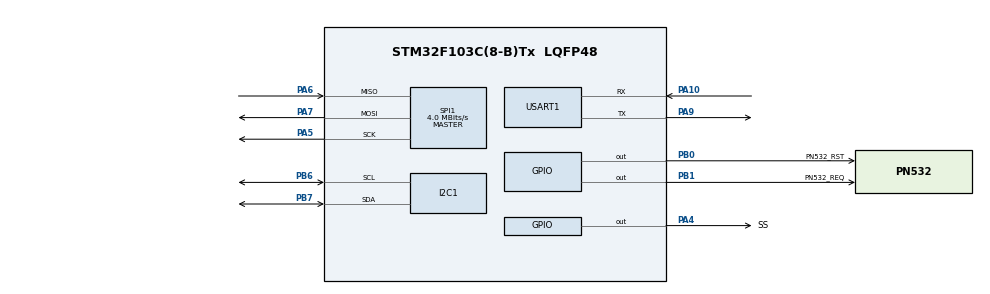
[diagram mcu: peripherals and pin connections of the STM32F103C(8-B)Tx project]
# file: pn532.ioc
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Mcu.Family=STM32F1
Mcu.Name=STM32F103C(8-B)Tx
Mcu.Package=LQFP48
NVIC.PriorityGroup=NVIC_PRIORITYGROUP_4
PA10.Mode=Asynchronous
PA10.Signal=USART1_RX
PA13.Mode=Serial_Wire
PA13.Signal=SYS_JTMS-SWDIO
PA14.Mode=Serial_Wire
PA14.Signal=SYS_JTCK-SWCLK
PA4.GPIO_Label=SS
PA4.GPIO_PuPd=GPIO_PULLUP
PA4.Signal=GPIO_Output
PA5.Mode=Full_Duplex_Master
PA5.Signal=SPI1_SCK
PA6.Mode=Full_Duplex_Master
PA6.Signal=SPI1_MISO
PA7.Mode=Full_Duplex_Master
PA7.Signal=SPI1_MOSI
PA9.Mode=Asynchronous
PA9.Signal=USART1_TX
PB0.GPIO_Label=PN532_RST
PB0.GPIO_PuPd=GPIO_PULLUP
PB0.Signal=GPIO_Output
PB1.GPIO_Label=PN532_REQ
PB1.GPIO_PuPd=GPIO_PULLUP
PB1.Signal=GPIO_Output
PB6.Mode=I2C
PB6.Signal=I2C1_SCL
PB7.Mode=I2C
PB7.Signal=I2C1_SDA
ProjectManager.HeapSize=0x200
ProjectManager.StackSize=0x400
ProjectManager.TargetToolchain=STM32CubeIDE
RCC.APB1Freq_Value=8000000
RCC.APB2Freq_Value=8000000
SPI1.CalculateBaudRate=4.0 MBits/s
SPI1.Direction=SPI_DIRECTION_2LINES
SPI1.Mode=SPI_MODE_MASTER
SPI1.VirtualType=VM_MASTER
USART1.VirtualMode=VM_ASYNC
board=custom

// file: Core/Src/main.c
/* USER CODE BEGIN Header */
/**
  ******************************************************************************
  * @file           : main.c
  * @brief          : Main program body
  ******************************************************************************
  * @attention
  *
  * <h2><center>&copy; Copyright (c) 2023 STMicroelectronics.
  * All rights reserved.</center></h2>
  *
  * This software component is licensed by ST under BSD 3-Clause license,
  * the "License"; You may not use this file except in compliance with the
  * License. You may obtain a copy of the License at:
  *                        opensource.org/licenses/BSD-3-Clause
  *
  ******************************************************************************
  */
/* USER CODE END Header */
#include "main.h"
#include "pn532_stm32f1.h"

I2C_HandleTypeDef hi2c1;

SPI_HandleTypeDef hspi1;

UART_HandleTypeDef huart1;

void SystemClock_Config(void);
static void MX_GPIO_Init(void);
static void MX_I2C1_Init(void);
static void MX_SPI1_Init(void);
static void MX_USART1_UART_Init(void);

int main(void)
{
	  uint8_t buff[255];
	  uint8_t uid[MIFARE_UID_MAX_LENGTH];
	  int32_t uid_len = 0;
	  uint32_t check = 0;
  /* MCU Configuration--------------------------------------------------------*/

  /* Reset of all peripherals, Initializes the Flash interface and the Systick. */
  HAL_Init();

  /* Configure the system clock */
  SystemClock_Config();

  /* Initialize all configured peripherals */
  MX_GPIO_Init();
  MX_I2C1_Init();
  MX_SPI1_Init();
  MX_USART1_UART_Init();
  /* USER CODE BEGIN 2 */
  PN532 pn532;
  /* USER CODE END 2 */
  //PN532_SPI_Init(&pn532);
  PN532_I2C_Init(&pn532);
  PN532_GetFirmwareVersion(&pn532, buff);
  if (PN532_GetFirmwareVersion(&pn532, buff) == PN532_STATUS_OK) {
   // printf("Found PN532 with firmware version: %d.%d\r\n", buff[1], buff[2]);
	  check = 1;
  } else {
   // return -1;
	  check = 0;
  }
  PN532_SamConfiguration(&pn532);
  check = 2;
 // printf("Waiting for RFID/NFC card...\r\n");
  /* Infinite loop */
  while (1)
  {
	    uid_len = PN532_ReadPassiveTarget(&pn532, uid, PN532_MIFARE_ISO14443A, 1000);
	    if (uid_len == PN532_STATUS_ERROR) {
	      printf(".");
	    } else {
	      printf("Found card with UID: ");
	      for (uint8_t i = 0; i < uid_len; i++) {
	        printf("%02x ", uid[i]);
	      }
	      printf("\r\n");
	    }
  }
}

void SystemClock_Config(void)
{
  RCC_OscInitTypeDef RCC_OscInitStruct = {0};
  RCC_ClkInitTypeDef RCC_ClkInitStruct = {0};

  /** Initializes the RCC Oscillators according to the specified parameters
  * in the RCC_OscInitTypeDef structure.
  */
  RCC_OscInitStruct.OscillatorType = RCC_OSCILLATORTYPE_HSI;
  RCC_OscInitStruct.HSIState = RCC_HSI_ON;
  RCC_OscInitStruct.HSICalibrationValue = RCC_HSICALIBRATION_DEFAULT;
  RCC_OscInitStruct.PLL.PLLState = RCC_PLL_NONE;
  if (HAL_RCC_OscConfig(&RCC_OscInitStruct) != HAL_OK)
  {
    Error_Handler();
  }
  /** Initializes the CPU, AHB and APB buses clocks
  */
  RCC_ClkInitStruct.ClockType = RCC_CLOCKTYPE_HCLK|RCC_CLOCKTYPE_SYSCLK
                              |RCC_CLOCKTYPE_PCLK1|RCC_CLOCKTYPE_PCLK2;
  RCC_ClkInitStruct.SYSCLKSource = RCC_SYSCLKSOURCE_HSI;
  RCC_ClkInitStruct.AHBCLKDivider = RCC_SYSCLK_DIV1;
  RCC_ClkInitStruct.APB1CLKDivider = RCC_HCLK_DIV1;
  RCC_ClkInitStruct.APB2CLKDivider = RCC_HCLK_DIV1;

  if (HAL_RCC_ClockConfig(&RCC_ClkInitStruct, FLASH_LATENCY_0) != HAL_OK)
  {
    Error_Handler();
  }
}

static void MX_I2C1_Init(void)
{

  hi2c1.Instance = I2C1;
  hi2c1.Init.ClockSpeed = 100000;
  hi2c1.Init.DutyCycle = I2C_DUTYCYCLE_2;
  hi2c1.Init.OwnAddress1 = 0;
  hi2c1.Init.AddressingMode = I2C_ADDRESSINGMODE_7BIT;
  hi2c1.Init.DualAddressMode = I2C_DUALADDRESS_DISABLE;
  hi2c1.Init.OwnAddress2 = 0;
  hi2c1.Init.GeneralCallMode = I2C_GENERALCALL_DISABLE;
  hi2c1.Init.NoStretchMode = I2C_NOSTRETCH_DISABLE;
  if (HAL_I2C_Init(&hi2c1) != HAL_OK)
  {
    Error_Handler();
  }

}

static void MX_SPI1_Init(void)
{

  /* SPI1 parameter configuration*/
  hspi1.Instance = SPI1;
  hspi1.Init.Mode = SPI_MODE_MASTER;
  hspi1.Init.Direction = SPI_DIRECTION_2LINES;
  hspi1.Init.DataSize = SPI_DATASIZE_8BIT;
  hspi1.Init.CLKPolarity = SPI_POLARITY_LOW;
  hspi1.Init.CLKPhase = SPI_PHASE_1EDGE;
  hspi1.Init.NSS = SPI_NSS_SOFT;
  hspi1.Init.BaudRatePrescaler = SPI_BAUDRATEPRESCALER_2;
  hspi1.Init.FirstBit = SPI_FIRSTBIT_MSB;
  hspi1.Init.TIMode = SPI_TIMODE_DISABLE;
  hspi1.Init.CRCCalculation = SPI_CRCCALCULATION_DISABLE;
  hspi1.Init.CRCPolynomial = 10;
  if (HAL_SPI_Init(&hspi1) != HAL_OK)
  {
    Error_Handler();
  }

}

static void MX_USART1_UART_Init(void)
{

  huart1.Instance = USART1;
  huart1.Init.BaudRate = 115200;
  huart1.Init.WordLength = UART_WORDLENGTH_8B;
  huart1.Init.StopBits = UART_STOPBITS_1;
  huart1.Init.Parity = UART_PARITY_NONE;
  huart1.Init.Mode = UART_MODE_TX_RX;
  huart1.Init.HwFlowCtl = UART_HWCONTROL_NONE;
  huart1.Init.OverSampling = UART_OVERSAMPLING_16;
  if (HAL_UART_Init(&huart1) != HAL_OK)
  {
    Error_Handler();
  }

}

static void MX_GPIO_Init(void)
{
  GPIO_InitTypeDef GPIO_InitStruct = {0};

  /* GPIO Ports Clock Enable */
  __HAL_RCC_GPIOA_CLK_ENABLE();
  __HAL_RCC_GPIOB_CLK_ENABLE();

  /*Configure GPIO pin Output Level */
  HAL_GPIO_WritePin(SS_GPIO_Port, SS_Pin, GPIO_PIN_RESET);

  /*Configure GPIO pin Output Level */
  HAL_GPIO_WritePin(GPIOB, PN532_RST_Pin|PN532_REQ_Pin, GPIO_PIN_RESET);

  /*Configure GPIO pin : SS_Pin */
  GPIO_InitStruct.Pin = SS_Pin;
  GPIO_InitStruct.Mode = GPIO_MODE_OUTPUT_PP;
  GPIO_InitStruct.Pull = GPIO_PULLUP;
  GPIO_InitStruct.Speed = GPIO_SPEED_FREQ_LOW;
  HAL_GPIO_Init(SS_GPIO_Port, &GPIO_InitStruct);

  /*Configure GPIO pins : PN532_RST_Pin PN532_REQ_Pin */
  GPIO_InitStruct.Pin = PN532_RST_Pin|PN532_REQ_Pin;
  GPIO_InitStruct.Mode = GPIO_MODE_OUTPUT_PP;
  GPIO_InitStruct.Pull = GPIO_PULLUP;
  GPIO_InitStruct.Speed = GPIO_SPEED_FREQ_LOW;
  HAL_GPIO_Init(GPIOB, &GPIO_InitStruct);

}

void Error_Handler(void)
{
  __disable_irq();
  while (1)
  {
  }
}

/************************ (C) COPYRIGHT STMicroelectronics *****END OF FILE****/
